# STM32F427xx register map
File version: 1.0
Registers are 32-bit, read-write, reset 0x0 unless marked. A register's access mark holds for its fields unless they carry their own. Offsets are from the block's base; [hi:lo] are bit positions; 'fields as' and 'values as' point back to an identical list.

## FMC
Base 0xA0000000
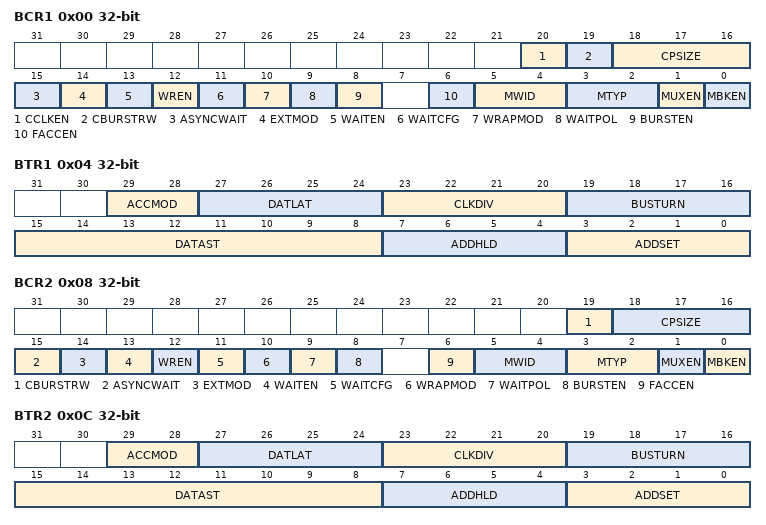
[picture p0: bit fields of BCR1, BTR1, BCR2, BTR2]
0x00 BCR1 — NOR/PSRAM chip-select control register(BCR) and chip-select timing register(BTR)
  [20] CCLKEN — Continuous clock enable
  [19] CBURSTRW — Write burst enable
  [18:16] CPSIZE — CRAM page size
  [15] ASYNCWAIT — Asynchronous wait
  [14] EXTMOD — Extended mode enable
  [13] WAITEN — Wait enable bit
  [12] WREN — Write enable bit
  [11] WAITCFG — Wait timing configuration
  [10] WRAPMOD — Wrapped burst mode support
  [9] WAITPOL — Wait signal polarity bit
  [8] BURSTEN — Burst enable bit
  [6] FACCEN — Flash access enable
  [5:4] MWID — MWID[1:0] bits (Memory data bus width)
  [3:2] MTYP — MTYP[1:0] bits (Memory type)
  [1] MUXEN — Address/data multiplexing enable bit
  [0] MBKEN — Memory bank enable bit
0x04 BTR1 — NOR/PSRAM chip-select control register(BCR) and chip-select timing register(BTR)
  [29:28] ACCMOD — ACCMOD[1:0] bits (Access mode)
  [27:24] DATLAT — DATLA[3:0] bits (Data latency)
  [23:20] CLKDIV — CLKDIV[3:0] bits (Clock divide ratio)
  [19:16] BUSTURN — BUSTURN[3:0] bits (Bus turnaround phase duration)
  [15:8] DATAST — DATAST [3:0] bits (Data-phase duration)
  [7:4] ADDHLD — ADDHLD[3:0] bits (Address-hold phase duration)
  [3:0] ADDSET — ADDSET[3:0] bits (Address setup phase duration)
0x08 BCR2 — NOR/PSRAM chip-select control register(BCR) and chip-select timing register(BTR)
  [19] CBURSTRW — Write burst enable
  [18:16] CPSIZE — CRAM page size
  [15] ASYNCWAIT — Asynchronous wait
  [14] EXTMOD — Extended mode enable
  [13] WAITEN — Wait enable bit
  [12] WREN — Write enable bit
  [11] WAITCFG — Wait timing configuration
  [10] WRAPMOD — Wrapped burst mode support
  [9] WAITPOL — Wait signal polarity bit
  [8] BURSTEN — Burst enable bit
  [6] FACCEN — Flash access enable
  [5:4] MWID — MWID[1:0] bits (Memory data bus width)
  [3:2] MTYP — MTYP[1:0] bits (Memory type)
  [1] MUXEN — Address/data multiplexing enable bit
  [0] MBKEN — Memory bank enable bit
0x0C BTR2 — NOR/PSRAM chip-select control register(BCR) and chip-select timing register(BTR)
  fields as BTR1
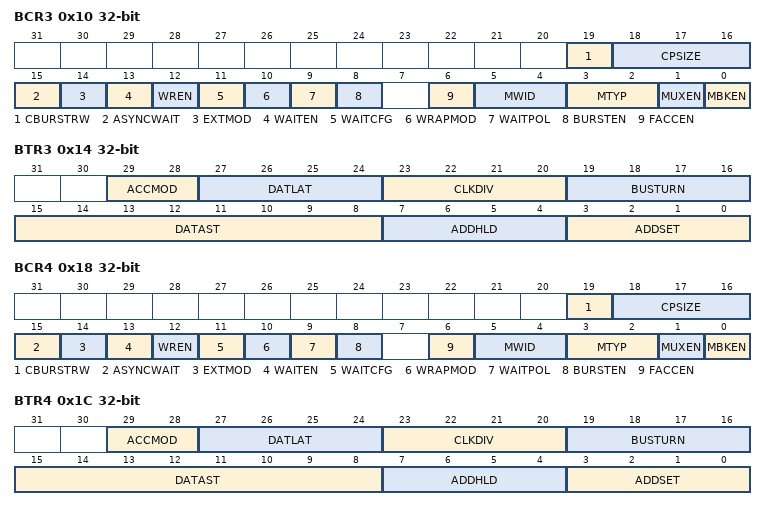
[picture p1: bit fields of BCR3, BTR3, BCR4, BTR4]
0x10 BCR3 — NOR/PSRAM chip-select control register(BCR) and chip-select timing register(BTR)
  fields as BCR2
0x14 BTR3 — NOR/PSRAM chip-select control register(BCR) and chip-select timing register(BTR)
  fields as BTR1
0x18 BCR4 — NOR/PSRAM chip-select control register(BCR) and chip-select timing register(BTR)
  fields as BCR2
0x1C BTR4 — NOR/PSRAM chip-select control register(BCR) and chip-select timing register(BTR)
  fields as BTR1
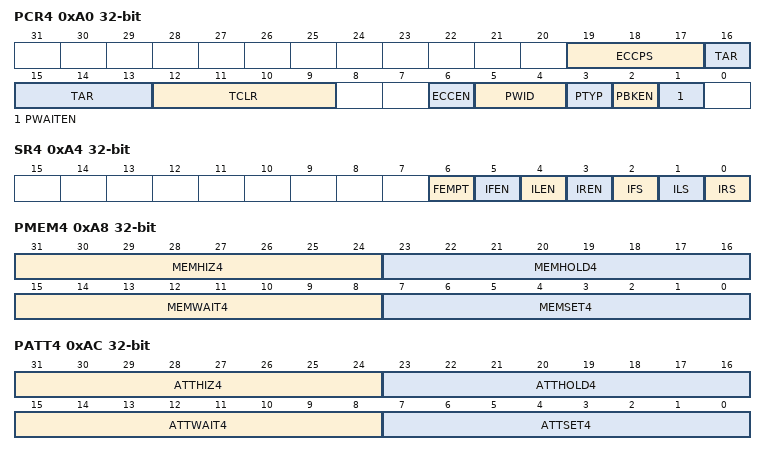
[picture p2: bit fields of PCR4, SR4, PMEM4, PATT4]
0xA0 PCR4 — PC Card control register 4
  [19:17] ECCPS — ECCPS[2:0] bits (ECC page size)
  [16:13] TAR — TAR[3:0] bits (ALE to RE delay)
  [12:9] TCLR — TCLR[3:0] bits (CLE to RE delay)
  [6] ECCEN — ECC computation logic enable bit
  [5:4] PWID — PWID[1:0] bits (NAND Flash databus width)
  [3] PTYP — Memory type
  [2] PBKEN — PC Card/NAND Flash memory bank enable bit
  [1] PWAITEN — Wait feature enable bit
0xA4 SR4 — PC Card FIFO status and interrupt register 4
  [6] FEMPT — FIFO empty
  [5] IFEN — Interrupt Falling Edge detection Enable bit
  [4] ILEN — Interrupt Level detection Enable bit
  [3] IREN — Interrupt Rising Edge detection Enable bit
  [2] IFS — Interrupt Falling Edge status
  [1] ILS — Interrupt Level status
  [0] IRS — Interrupt Rising Edge status
0xA8 PMEM4 — PC Card Common memory space timing register 4
  [31:24] MEMHIZ4 — MEMHIZ4[7:0] bits (Common memory 4 databus HiZ time)
  [23:16] MEMHOLD4 — MEMHOLD4[7:0] bits (Common memory 4 hold time)
  [15:8] MEMWAIT4 — MEMWAIT4[7:0] bits (Common memory 4 wait time)
  [7:0] MEMSET4 — MEMSET4[7:0] bits (Common memory 4 setup time)
0xAC PATT4 — PC Card Attribute memory space timing register 4
  [31:24] ATTHIZ4 — ATTHIZ4[7:0] bits (Attribute memory 4 databus HiZ time)
  [23:16] ATTHOLD4 — ATTHOLD4[7:0] bits (Attribute memory 4 hold time)
  [15:8] ATTWAIT4 — ATTWAIT4[7:0] bits (Attribute memory 4 wait time)
  [7:0] ATTSET4 — ATTSET4[7:0] bits (Attribute memory 4 setup time)
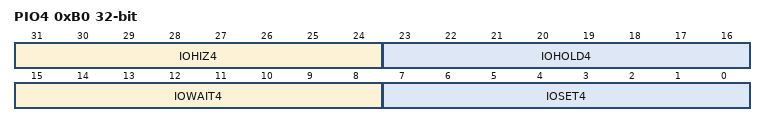
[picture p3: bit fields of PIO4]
0xB0 PIO4 — PC Card I/O space timing register 4
  [31:24] IOHIZ4 — IOHIZ4[7:0] bits (I/O 4 databus HiZ time)
  [23:16] IOHOLD4 — IOHOLD4[7:0] bits (I/O 4 hold time)
  [15:8] IOWAIT4 — IOWAIT4[7:0] bits (I/O 4 wait time)
  [7:0] IOSET4 — IOSET4[7:0] bits (I/O 4 setup time)
